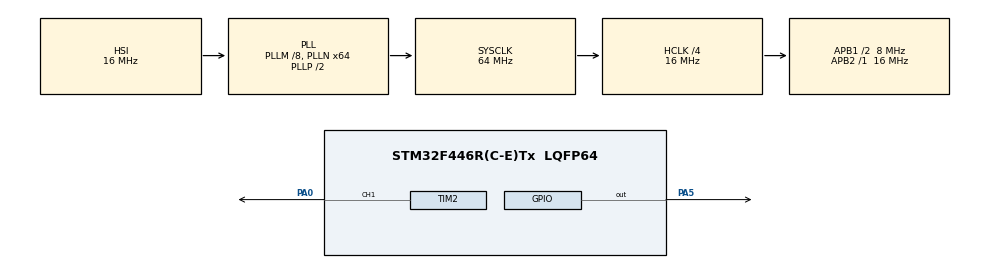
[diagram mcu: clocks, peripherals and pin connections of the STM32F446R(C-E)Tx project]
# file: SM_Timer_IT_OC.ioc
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Mcu.Family=STM32F4
Mcu.Name=STM32F446R(C-E)Tx
Mcu.Package=LQFP64
NVIC.PriorityGroup=NVIC_PRIORITYGROUP_0
NVIC.TIM2_IRQn=true\:0\:0\:false\:false\:true\:true\:true\:true
PA0-WKUP.Signal=S_TIM2_CH1_ETR
PA5.Signal=GPIO_Output
ProjectManager.HeapSize=0x200
ProjectManager.StackSize=0x400
ProjectManager.TargetToolchain=STM32CubeIDE
RCC.AHBCLKDivider=RCC_SYSCLK_DIV4
RCC.AHBFreq_Value=16000000
RCC.APB1CLKDivider=RCC_HCLK_DIV2
RCC.APB1Freq_Value=8000000
RCC.APB1TimFreq_Value=16000000
RCC.APB2Freq_Value=16000000
RCC.APB2TimFreq_Value=16000000
RCC.CortexFreq_Value=16000000
RCC.FLatency-AdvancedSettings=FLASH_LATENCY_0
RCC.HCLKFreq_Value=16000000
RCC.HSE_VALUE=8000000
RCC.HSI_VALUE=16000000
RCC.LSE_VALUE=32768
RCC.PLLM=8
RCC.PLLN=64
RCC.SYSCLKFreq_VALUE=64000000
RCC.SYSCLKSource=RCC_SYSCLKSOURCE_PLLCLK
RCC.USBFreq_Value=64000000
RCC.VCOOutputFreq_Value=128000000
SH.S_TIM2_CH1_ETR.0=TIM2_CH1,Output Compare1 CH1
TIM2.Channel-Output\ Compare1\ CH1=TIM_CHANNEL_1
TIM2.Period=5000
TIM2.Prescaler=15999
TIM2.Pulse-Output\ Compare1\ CH1=1000
board=NUCLEO-F446RE

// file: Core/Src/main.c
/* USER CODE BEGIN Header */
/**
  ******************************************************************************
  * @file           : main.c
  * @brief          : Main program body
  ******************************************************************************
  * @attention
  *
  * Copyright (c) 2025 STMicroelectronics.
  * All rights reserved.
  *
  * This software is licensed under terms that can be found in the LICENSE file
  * in the root directory of this software component.
  * If no LICENSE file comes with this software, it is provided AS-IS.
  *
  ******************************************************************************
  */
/* USER CODE END Header */
#include "main.h"

/* USER CODE BEGIN Includes */
#include <stdio.h>
/* USER CODE END Includes */

TIM_HandleTypeDef htim2;

void SystemClock_Config(void);
static void MX_GPIO_Init(void);
static void MX_TIM2_Init(void);

/* USER CODE BEGIN 0 */
//int _write(int file, char *ptr, int len)
//{
//    HAL_UART_Transmit(&huart2, (uint8_t *)ptr, len, HAL_MAX_DELAY);
//    return len;
//}
/* USER CODE END 0 */

int main(void)
{

  /* MCU Configuration--------------------------------------------------------*/

  /* Reset of all peripherals, Initializes the Flash interface and the Systick. */
  HAL_Init();

  /* Configure the system clock */
  SystemClock_Config();

  /* Initialize all configured peripherals */
  MX_GPIO_Init();
  MX_TIM2_Init();
  /* USER CODE BEGIN 2 */
//  HAL_TIM_OC_Start(&htim2, TIM_CHANNEL_1);
  HAL_TIM_OC_Start_IT(&htim2, TIM_CHANNEL_1);

//  uint32_t status;
//  uint8_t bit_1;
  /* USER CODE END 2 */

  /* Infinite loop */
  while (1)
  {

    /* USER CODE BEGIN 3 */
//	  status = htim2.Instance->DIER;
//	  bit_1 = status & (1 << 1);
//	  if(bit_1){
//		  HAL_GPIO_TogglePin(GPIOA, GPIO_PIN_5);
//		  // clear the bit
//		  status = status & ~(1 << 1);
//		  htim2.Instance->DIER = status;
//	  }
  }
  /* USER CODE END 3 */
}

void SystemClock_Config(void)
{
  RCC_OscInitTypeDef RCC_OscInitStruct = {0};
  RCC_ClkInitTypeDef RCC_ClkInitStruct = {0};

  /** Configure the main internal regulator output voltage
  */
  __HAL_RCC_PWR_CLK_ENABLE();
  __HAL_PWR_VOLTAGESCALING_CONFIG(PWR_REGULATOR_VOLTAGE_SCALE3);

  /** Initializes the RCC Oscillators according to the specified parameters
  * in the RCC_OscInitTypeDef structure.
  */
  RCC_OscInitStruct.OscillatorType = RCC_OSCILLATORTYPE_HSI;
  RCC_OscInitStruct.HSIState = RCC_HSI_ON;
  RCC_OscInitStruct.HSICalibrationValue = RCC_HSICALIBRATION_DEFAULT;
  RCC_OscInitStruct.PLL.PLLState = RCC_PLL_ON;
  RCC_OscInitStruct.PLL.PLLSource = RCC_PLLSOURCE_HSI;
  RCC_OscInitStruct.PLL.PLLM = 8;
  RCC_OscInitStruct.PLL.PLLN = 64;
  RCC_OscInitStruct.PLL.PLLP = RCC_PLLP_DIV2;
  RCC_OscInitStruct.PLL.PLLQ = 2;
  RCC_OscInitStruct.PLL.PLLR = 2;
  if (HAL_RCC_OscConfig(&RCC_OscInitStruct) != HAL_OK)
  {
    Error_Handler();
  }

  /** Initializes the CPU, AHB and APB buses clocks
  */
  RCC_ClkInitStruct.ClockType = RCC_CLOCKTYPE_HCLK|RCC_CLOCKTYPE_SYSCLK
                              |RCC_CLOCKTYPE_PCLK1|RCC_CLOCKTYPE_PCLK2;
  RCC_ClkInitStruct.SYSCLKSource = RCC_SYSCLKSOURCE_PLLCLK;
  RCC_ClkInitStruct.AHBCLKDivider = RCC_SYSCLK_DIV4;
  RCC_ClkInitStruct.APB1CLKDivider = RCC_HCLK_DIV2;
  RCC_ClkInitStruct.APB2CLKDivider = RCC_HCLK_DIV1;

  if (HAL_RCC_ClockConfig(&RCC_ClkInitStruct, FLASH_LATENCY_0) != HAL_OK)
  {
    Error_Handler();
  }
}

static void MX_TIM2_Init(void)
{

  TIM_MasterConfigTypeDef sMasterConfig = {0};
  TIM_OC_InitTypeDef sConfigOC = {0};

  htim2.Instance = TIM2;
  htim2.Init.Prescaler = 15999;
  htim2.Init.CounterMode = TIM_COUNTERMODE_UP;
  htim2.Init.Period = 5000;
  htim2.Init.ClockDivision = TIM_CLOCKDIVISION_DIV1;
  htim2.Init.AutoReloadPreload = TIM_AUTORELOAD_PRELOAD_DISABLE;
  if (HAL_TIM_OC_Init(&htim2) != HAL_OK)
  {
    Error_Handler();
  }
  sMasterConfig.MasterOutputTrigger = TIM_TRGO_RESET;
  sMasterConfig.MasterSlaveMode = TIM_MASTERSLAVEMODE_DISABLE;
  if (HAL_TIMEx_MasterConfigSynchronization(&htim2, &sMasterConfig) != HAL_OK)
  {
    Error_Handler();
  }
  sConfigOC.OCMode = TIM_OCMODE_TIMING;
  sConfigOC.Pulse = 1000;
  sConfigOC.OCPolarity = TIM_OCPOLARITY_HIGH;
  sConfigOC.OCFastMode = TIM_OCFAST_DISABLE;
  if (HAL_TIM_OC_ConfigChannel(&htim2, &sConfigOC, TIM_CHANNEL_1) != HAL_OK)
  {
    Error_Handler();
  }
  HAL_TIM_MspPostInit(&htim2);

}

static void MX_GPIO_Init(void)
{
  GPIO_InitTypeDef GPIO_InitStruct = {0};

  /* GPIO Ports Clock Enable */
  __HAL_RCC_GPIOA_CLK_ENABLE();

  /*Configure GPIO pin Output Level */
  HAL_GPIO_WritePin(GPIOA, GPIO_PIN_5, GPIO_PIN_RESET);

  /*Configure GPIO pin : PA5 */
  GPIO_InitStruct.Pin = GPIO_PIN_5;
  GPIO_InitStruct.Mode = GPIO_MODE_OUTPUT_PP;
  GPIO_InitStruct.Pull = GPIO_NOPULL;
  GPIO_InitStruct.Speed = GPIO_SPEED_FREQ_LOW;
  HAL_GPIO_Init(GPIOA, &GPIO_InitStruct);

}

void Error_Handler(void)
{
  __disable_irq();
  while (1)
  {
  }
}
